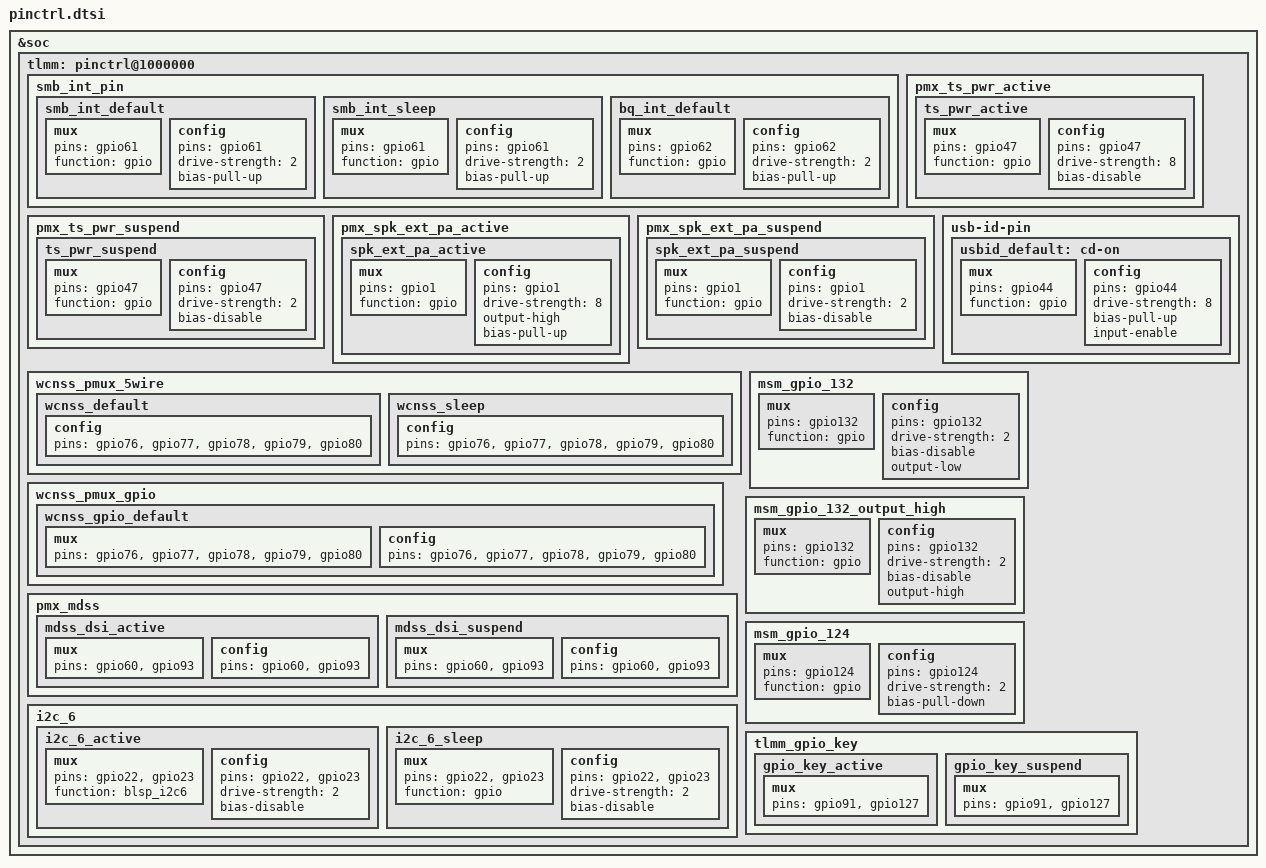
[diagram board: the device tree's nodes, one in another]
&soc {
	tlmm: pinctrl@1000000 {
	smb_int_pin {
			smb_int_default: smb_int_default {
				mux {
					pins = "gpio61";
					function ="gpio";
				};
				config {
					pins = "gpio61";
					drive-strength = <2>;
					bias-pull-up;
				};
			};

			smb_int_sleep: smb_int_sleep {
				mux {
					pins = "gpio61";
					function ="gpio";
				};
				config {
					pins = "gpio61";
					drive-strength = <2>;
					bias-pull-up;
				};
			};

			bq_int_default: bq_int_default {
				mux {
					pins = "gpio62";
					function ="gpio";
				};
				config {
					pins = "gpio62";
					drive-strength = <2>;   /* 2 MA */
					bias-pull-up;           /* PULL UP*/
				};
			};
		};

		pmx_ts_pwr_active {
			ts_pwr_active: ts_pwr_active {
				mux {
					pins = "gpio47";
					function = "gpio";
				};

				config {
					pins = "gpio47";
					drive-strength = <8>;
					bias-disable;
				};
			};
		};

		pmx_ts_pwr_suspend {
			ts_pwr_suspend: ts_pwr_suspend {
				mux {
					pins = "gpio47";
					function = "gpio";
				};

				config {
					pins = "gpio47";
					drive-strength = <2>;
					bias-disable;
				};
			};
		};

			pmx_spk_ext_pa_active{
				spk_ext_pa_active: spk_ext_pa_active {
					mux {
					pins = "gpio1";
					function = "gpio";
					};

				config {
					pins = "gpio1";
					drive-strength = <8>;
					output-high;
					bias-pull-up;
					};
				};
			};

			pmx_spk_ext_pa_suspend{
				spk_ext_pa_suspend: spk_ext_pa_suspend {
					mux {
					pins = "gpio1";
					function = "gpio";
					};

				config {
					pins = "gpio1";
					drive-strength = <2>;
					bias-disable;
					};
				};
			};

		wcnss_pmux_5wire {
			wcnss_default: wcnss_default {
				config {
					pins = "gpio76", "gpio77",
					     "gpio78", "gpio79",
					     "gpio80";
				};
			};

			wcnss_sleep: wcnss_sleep {
				config {
					pins = "gpio76", "gpio77",
					     "gpio78", "gpio79",
					     "gpio80";
				};
			};
		};

		wcnss_pmux_gpio: wcnss_pmux_gpio {
			wcnss_gpio_default: wcnss_gpio_default {
				mux {
					pins = "gpio76", "gpio77",
					     "gpio78", "gpio79",
					     "gpio80";
				};

				config {
					pins = "gpio76", "gpio77",
					     "gpio78", "gpio79",
					     "gpio80";
				};
			};
		};

		pmx_mdss: pmx_mdss {
			mdss_dsi_active: mdss_dsi_active {
				mux {
					pins = "gpio60", "gpio93";
				};

				config {
					pins = "gpio60", "gpio93";
				};
			};
			mdss_dsi_suspend: mdss_dsi_suspend {
				mux {
					pins = "gpio60", "gpio93";
				};

				config {
					pins = "gpio60", "gpio93";
				};
			};
		};

		usb-id-pin {
			usbid_default: cd-on{
				mux {
					pins = "gpio44";
					function = "gpio";
				};
				config {
					pins = "gpio44";
					drive-strength = <8>;
					bias-pull-up;
					input-enable;
				};
			};
		};

		i2c_6 {
			i2c_6_active: i2c_6_active {
				mux {
					pins = "gpio22", "gpio23";
					function = "blsp_i2c6";
				};

				config {
					pins = "gpio22", "gpio23";
					drive-strength = <2>;
					bias-disable;
				};
			};

			i2c_6_sleep: i2c_6_sleep {
				mux {
					pins = "gpio22", "gpio23";
					function = "gpio";
				};

				config {
					pins = "gpio22", "gpio23";
					drive-strength = <2>;
					bias-disable;
				};
			};
		};

		msm_gpio_132:msm_gpio_132 {
			mux{
				pins="gpio132";
				function= "gpio";
			};
			config {
				pins= "gpio132";
				drive-strength = <2>;
				bias-disable;
				output-low;

			};
		};

		msm_gpio_132_output_high:msm_gpio_132_output_high {
				mux {
					pins = "gpio132";
					function = "gpio";

				};
				config{
					pins = "gpio132";
					drive-strength = <2>;
					bias-disable;
					output-high;
				};

        };

		msm_gpio_124:msm_gpio_124{
			mux{
				pins = "gpio124";
				function = "gpio";
			};
			config{
				pins = "gpio124";
				drive-strength=<2>;
				bias-pull-down;
			};
		};

		tlmm_gpio_key {
			gpio_key_active: gpio_key_active {
				mux {
					pins = "gpio91", "gpio127";
				};
			};

			gpio_key_suspend: gpio_key_suspend {
				mux {
					pins = "gpio91", "gpio127";
				};
			};
		};
	};
};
